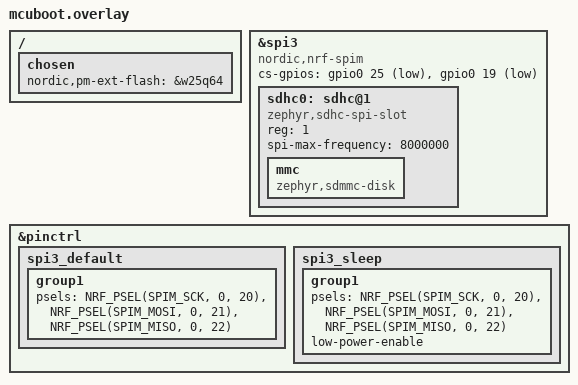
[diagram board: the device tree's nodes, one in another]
/ {
    chosen {
        nordic,pm-ext-flash = &w25q64;
    };
};

&spi3 {
    compatible = "nordic,nrf-spim";
    status = "okay";
    cs-gpios = <&gpio0 25 GPIO_ACTIVE_LOW>,<&gpio0 19 GPIO_ACTIVE_LOW>;

    sdhc0: sdhc@1 {
        compatible = "zephyr,sdhc-spi-slot";
        reg = <1>;
        status = "okay";
        mmc {
            compatible = "zephyr,sdmmc-disk";
            status = "okay";
        };
        spi-max-frequency = <8000000>;
    };
};

&pinctrl {
    spi3_default: spi3_default {
        group1 {
            psels = <NRF_PSEL(SPIM_SCK, 0, 20)>,
                    <NRF_PSEL(SPIM_MOSI, 0, 21)>,
                    <NRF_PSEL(SPIM_MISO, 0, 22)>;
        };
    };

    spi3_sleep: spi3_sleep {
        group1 {
            psels = <NRF_PSEL(SPIM_SCK, 0, 20)>,
                    <NRF_PSEL(SPIM_MOSI, 0, 21)>,
                    <NRF_PSEL(SPIM_MISO, 0, 22)>;
            low-power-enable;
        };
    };
};
